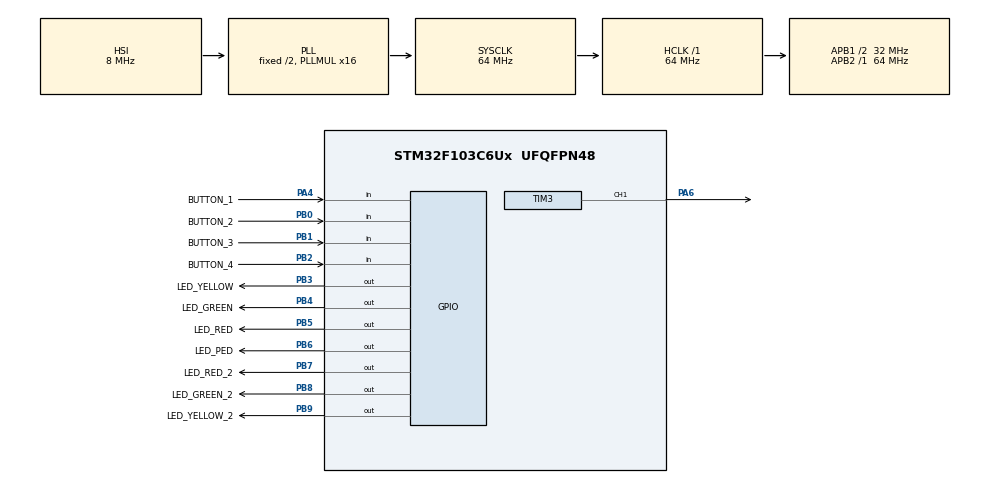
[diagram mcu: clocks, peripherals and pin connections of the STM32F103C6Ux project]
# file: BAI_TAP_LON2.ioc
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Mcu.Family=STM32F1
Mcu.Name=STM32F103C6Ux
Mcu.Package=UFQFPN48
NVIC.PriorityGroup=NVIC_PRIORITYGROUP_4
NVIC.TIM2_IRQn=true\:0\:0\:false\:false\:true\:true\:true
PA4.GPIO_Label=BUTTON_1
PA4.Signal=GPIO_Input
PA6.Signal=S_TIM3_CH1
PB0.GPIO_Label=BUTTON_2
PB0.Signal=GPIO_Input
PB1.GPIO_Label=BUTTON_3
PB1.Signal=GPIO_Input
PB2.GPIO_Label=BUTTON_4
PB2.Signal=GPIO_Input
PB3.GPIO_Label=LED_YELLOW
PB3.Signal=GPIO_Output
PB4.GPIO_Label=LED_GREEN
PB4.Signal=GPIO_Output
PB5.GPIO_Label=LED_RED
PB5.Signal=GPIO_Output
PB6.GPIO_Label=LED_PED
PB6.Signal=GPIO_Output
PB7.GPIO_Label=LED_RED_2
PB7.Signal=GPIO_Output
PB8.GPIO_Label=LED_GREEN_2
PB8.Signal=GPIO_Output
PB9.GPIO_Label=LED_YELLOW_2
PB9.Signal=GPIO_Output
ProjectManager.HeapSize=0x200
ProjectManager.StackSize=0x400
ProjectManager.TargetToolchain=STM32CubeIDE
RCC.AHBFreq_Value=64000000
RCC.APB1CLKDivider=RCC_HCLK_DIV2
RCC.APB1Freq_Value=32000000
RCC.APB1TimFreq_Value=64000000
RCC.APB2Freq_Value=64000000
RCC.APB2TimFreq_Value=64000000
RCC.HCLKFreq_Value=64000000
RCC.PLLMUL=RCC_PLL_MUL16
RCC.SYSCLKFreq_VALUE=64000000
RCC.SYSCLKSource=RCC_SYSCLKSOURCE_PLLCLK
RCC.USBFreq_Value=64000000
SH.S_TIM3_CH1.0=TIM3_CH1,PWM Generation1 CH1
TIM2.Period=79
TIM2.Prescaler=7999
TIM3.Channel-PWM\ Generation1\ CH1=TIM_CHANNEL_1
TIM3.Period=999
TIM3.Prescaler=63
TIM3.Pulse-PWM\ Generation1\ CH1=500
VP_SYS_VS_ND.Mode=No_Debug
VP_TIM2_VS_ClockSourceINT.Mode=Internal
VP_TIM3_VS_ClockSourceINT.Mode=Internal
board=custom

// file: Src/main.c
/* USER CODE BEGIN Header */
/**
  ******************************************************************************
  * @file           : main.c
  * @brief          : Main program body
  ******************************************************************************
  * @attention
  *
  * <h2><center>&copy; Copyright (c) 2022 STMicroelectronics.
  * All rights reserved.</center></h2>
  *
  * This software component is licensed by ST under BSD 3-Clause license,
  * the "License"; You may not use this file except in compliance with the
  * License. You may obtain a copy of the License at:
  *                        opensource.org/licenses/BSD-3-Clause
  *
  ******************************************************************************
  */
/* USER CODE END Header */
#include "main.h"
#include "button.h"
#include "fsm_automatic.h"
#include "timer.h"
#include "global.h"

TIM_HandleTypeDef htim2;
TIM_HandleTypeDef htim3;

void SystemClock_Config(void);
static void MX_GPIO_Init(void);
static void MX_TIM2_Init(void);
static void MX_TIM3_Init(void);

int main(void)
{

  /* MCU Configuration--------------------------------------------------------*/

  /* Reset of all peripherals, Initializes the Flash interface and the Systick. */
  HAL_Init();

  /* Configure the system clock */
  SystemClock_Config();

  /* Initialize all configured peripherals */
  MX_GPIO_Init();
  MX_TIM2_Init();
  MX_TIM3_Init();
  /* USER CODE BEGIN 2 */
  HAL_TIM_Base_Start_IT (&htim2 );
  status = INIT;
  status1 = INIT;
  uint32_t PWM = 0;
  int count = 0;
  SCH_Init();
  SCH_Add_Task(fsm_automatic_run, 0, 1);    /* USER CODE BEGIN 3 */
  SCH_Add_Task(getKeyInput1, 0, 1);    /* USER CODE BEGIN 3 */
  SCH_Add_Task(getKeyInput2, 0, 1);    /* USER CODE BEGIN 3 */
  SCH_Add_Task(getKeyInput3, 0, 1);    /* USER CODE BEGIN 3 */
  SCH_Add_Task(getKeyInput4, 0, 1);    /* USER CODE BEGIN 3 */
  setTimer2(10);
  while (1)
  {
    /* USER CODE END WHILE */
	//HAL_GPIO_WritePin(GPIOB, LED_RED_Pin|LED_YELLOW_Pin, 1);
	SCH_Dispatch_Tasks();
	if(button_flag1 == 1)
	{
		status = AUTO_GREEN;
		button_flag1 = 0;
		__HAL_TIM_SET_COMPARE(&htim3, TIM_CHANNEL_1,0);
		count = 0;
		setTimer1(10);
	}
	if(button_flag2 == 1)
	{
		status = AUTO_YELLOW;
		button_flag2 = 0;
		__HAL_TIM_SET_COMPARE(&htim3, TIM_CHANNEL_1,0);
		count = 0;
		setTimer1(10);
	}
	if(button_flag3 == 1)
	{
		status = AUTO_RED;
		button_flag3 = 0;
		__HAL_TIM_SET_COMPARE(&htim3, TIM_CHANNEL_1,0);
		count = 0;
		setTimer1(10);
	}
	if(button_flag4 == 1)
	{
		status = AUTO_WHITE;
		button_flag4 = 0;
		HAL_TIM_PWM_Start (&htim3, TIM_CHANNEL_1);
		count = 1;
		setTimer1(10);
	}
	if(count == 1){
		if(timer2_flag == 1){
			__HAL_TIM_SET_COMPARE(&htim3, TIM_CHANNEL_1,PWM);
			PWM++;
			if(PWM == 950){
				PWM = 0;
			}
			setTimer2(10);
		}
	}
  }
}

void SystemClock_Config(void)
{
  RCC_OscInitTypeDef RCC_OscInitStruct = {0};
  RCC_ClkInitTypeDef RCC_ClkInitStruct = {0};

  /** Initializes the RCC Oscillators according to the specified parameters
  * in the RCC_OscInitTypeDef structure.
  */
  RCC_OscInitStruct.OscillatorType = RCC_OSCILLATORTYPE_HSI;
  RCC_OscInitStruct.HSIState = RCC_HSI_ON;
  RCC_OscInitStruct.HSICalibrationValue = RCC_HSICALIBRATION_DEFAULT;
  RCC_OscInitStruct.PLL.PLLState = RCC_PLL_ON;
  RCC_OscInitStruct.PLL.PLLSource = RCC_PLLSOURCE_HSI_DIV2;
  RCC_OscInitStruct.PLL.PLLMUL = RCC_PLL_MUL16;
  if (HAL_RCC_OscConfig(&RCC_OscInitStruct) != HAL_OK)
  {
    Error_Handler();
  }
  /** Initializes the CPU, AHB and APB buses clocks
  */
  RCC_ClkInitStruct.ClockType = RCC_CLOCKTYPE_HCLK|RCC_CLOCKTYPE_SYSCLK
                              |RCC_CLOCKTYPE_PCLK1|RCC_CLOCKTYPE_PCLK2;
  RCC_ClkInitStruct.SYSCLKSource = RCC_SYSCLKSOURCE_PLLCLK;
  RCC_ClkInitStruct.AHBCLKDivider = RCC_SYSCLK_DIV1;
  RCC_ClkInitStruct.APB1CLKDivider = RCC_HCLK_DIV2;
  RCC_ClkInitStruct.APB2CLKDivider = RCC_HCLK_DIV1;

  if (HAL_RCC_ClockConfig(&RCC_ClkInitStruct, FLASH_LATENCY_2) != HAL_OK)
  {
    Error_Handler();
  }
}

static void MX_TIM2_Init(void)
{

  TIM_ClockConfigTypeDef sClockSourceConfig = {0};
  TIM_MasterConfigTypeDef sMasterConfig = {0};

  htim2.Instance = TIM2;
  htim2.Init.Prescaler = 7999;
  htim2.Init.CounterMode = TIM_COUNTERMODE_UP;
  htim2.Init.Period = 79;
  htim2.Init.ClockDivision = TIM_CLOCKDIVISION_DIV1;
  htim2.Init.AutoReloadPreload = TIM_AUTORELOAD_PRELOAD_DISABLE;
  if (HAL_TIM_Base_Init(&htim2) != HAL_OK)
  {
    Error_Handler();
  }
  sClockSourceConfig.ClockSource = TIM_CLOCKSOURCE_INTERNAL;
  if (HAL_TIM_ConfigClockSource(&htim2, &sClockSourceConfig) != HAL_OK)
  {
    Error_Handler();
  }
  sMasterConfig.MasterOutputTrigger = TIM_TRGO_RESET;
  sMasterConfig.MasterSlaveMode = TIM_MASTERSLAVEMODE_DISABLE;
  if (HAL_TIMEx_MasterConfigSynchronization(&htim2, &sMasterConfig) != HAL_OK)
  {
    Error_Handler();
  }

}

static void MX_TIM3_Init(void)
{

  TIM_ClockConfigTypeDef sClockSourceConfig = {0};
  TIM_MasterConfigTypeDef sMasterConfig = {0};
  TIM_OC_InitTypeDef sConfigOC = {0};

  htim3.Instance = TIM3;
  htim3.Init.Prescaler = 63;
  htim3.Init.CounterMode = TIM_COUNTERMODE_UP;
  htim3.Init.Period = 999;
  htim3.Init.ClockDivision = TIM_CLOCKDIVISION_DIV1;
  htim3.Init.AutoReloadPreload = TIM_AUTORELOAD_PRELOAD_DISABLE;
  if (HAL_TIM_Base_Init(&htim3) != HAL_OK)
  {
    Error_Handler();
  }
  sClockSourceConfig.ClockSource = TIM_CLOCKSOURCE_INTERNAL;
  if (HAL_TIM_ConfigClockSource(&htim3, &sClockSourceConfig) != HAL_OK)
  {
    Error_Handler();
  }
  if (HAL_TIM_PWM_Init(&htim3) != HAL_OK)
  {
    Error_Handler();
  }
  sMasterConfig.MasterOutputTrigger = TIM_TRGO_RESET;
  sMasterConfig.MasterSlaveMode = TIM_MASTERSLAVEMODE_DISABLE;
  if (HAL_TIMEx_MasterConfigSynchronization(&htim3, &sMasterConfig) != HAL_OK)
  {
    Error_Handler();
  }
  sConfigOC.OCMode = TIM_OCMODE_PWM1;
  sConfigOC.Pulse = 500;
  sConfigOC.OCPolarity = TIM_OCPOLARITY_HIGH;
  sConfigOC.OCFastMode = TIM_OCFAST_DISABLE;
  if (HAL_TIM_PWM_ConfigChannel(&htim3, &sConfigOC, TIM_CHANNEL_1) != HAL_OK)
  {
    Error_Handler();
  }
  HAL_TIM_MspPostInit(&htim3);

}

static void MX_GPIO_Init(void)
{
  GPIO_InitTypeDef GPIO_InitStruct = {0};

  /* GPIO Ports Clock Enable */
  __HAL_RCC_GPIOA_CLK_ENABLE();
  __HAL_RCC_GPIOB_CLK_ENABLE();

  /*Configure GPIO pin Output Level */
  HAL_GPIO_WritePin(GPIOB, LED_YELLOW_Pin|LED_GREEN_Pin|LED_RED_Pin|LED_PED_Pin, GPIO_PIN_RESET);

  /*Configure GPIO pin : BUTTON_1_Pin */
  GPIO_InitStruct.Pin = BUTTON_1_Pin;
  GPIO_InitStruct.Mode = GPIO_MODE_INPUT;
  GPIO_InitStruct.Pull = GPIO_NOPULL;
  HAL_GPIO_Init(BUTTON_1_GPIO_Port, &GPIO_InitStruct);

  /*Configure GPIO pins : BUTTON_2_Pin BUTTON_3_Pin BUTTON_4_Pin */
  GPIO_InitStruct.Pin = BUTTON_2_Pin|BUTTON_3_Pin|BUTTON_4_Pin;
  GPIO_InitStruct.Mode = GPIO_MODE_INPUT;
  GPIO_InitStruct.Pull = GPIO_NOPULL;
  HAL_GPIO_Init(GPIOB, &GPIO_InitStruct);

  /*Configure GPIO pins : LED_YELLOW_Pin LED_GREEN_Pin LED_RED_Pin LED_PED_Pin */
  GPIO_InitStruct.Pin = LED_YELLOW_Pin|LED_GREEN_Pin|LED_RED_Pin|LED_PED_Pin;
  GPIO_InitStruct.Mode = GPIO_MODE_OUTPUT_PP;
  GPIO_InitStruct.Pull = GPIO_NOPULL;
  GPIO_InitStruct.Speed = GPIO_SPEED_FREQ_LOW;
  HAL_GPIO_Init(GPIOB, &GPIO_InitStruct);

}

/* USER CODE BEGIN 4 */
void HAL_TIM_PeriodElapsedCallback(TIM_HandleTypeDef *htim){
	timer_run();
	timer_run2();
	SCH_Update() ;
}
/* USER CODE END 4 */

void Error_Handler(void)
{
  __disable_irq();
  while (1)
  {
  }
}

/************************ (C) COPYRIGHT STMicroelectronics *****END OF FILE****/
